AUTOSAR XML (schema 4-3-1)
standard types defined: Boolean, UInt8, SInt8, UInt16, SInt16, UInt32, SInt32, boolean, uint8, sint8, uint16, sint16, uint32, sint32
package /Components
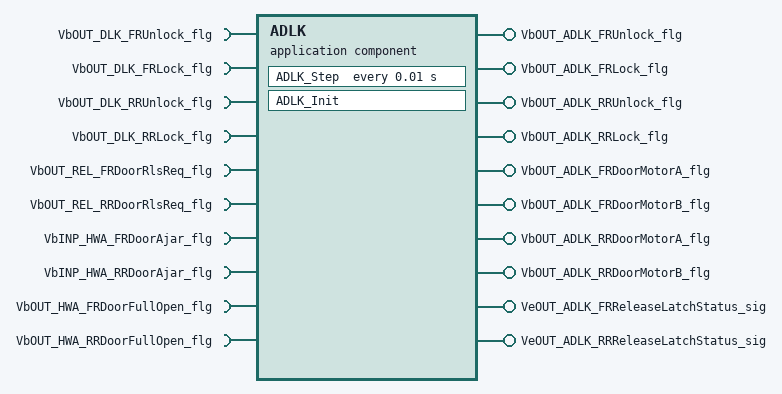
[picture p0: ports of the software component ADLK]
  application sw component type ADLK
    10 x require port:
      VbOUT_DLK_FRUnlock_flg: nonqueued-receiver-com-spec{data-element=VbOUT_DLK_FRUnlock_flg, init-value=FALSE}, required-interface=VbOUT_DLK_FRUnlock_flg
      VbOUT_DLK_FRLock_flg: nonqueued-receiver-com-spec{data-element=VbOUT_DLK_FRLock_flg, init-value=FALSE}, required-interface=VbOUT_DLK_FRLock_flg
      VbOUT_DLK_RRUnlock_flg: nonqueued-receiver-com-spec{data-element=VbOUT_DLK_RRUnlock_flg, init-value=FALSE}, required-interface=VbOUT_DLK_RRUnlock_flg
      VbOUT_DLK_RRLock_flg: nonqueued-receiver-com-spec{data-element=VbOUT_DLK_RRLock_flg, init-value=FALSE}, required-interface=VbOUT_DLK_RRLock_flg
      VbOUT_REL_FRDoorRlsReq_flg: nonqueued-receiver-com-spec{data-element=VbOUT_REL_FRDoorRlsReq_flg, init-value=FALSE}, required-interface=VbOUT_REL_FRDoorRlsReq_flg
      VbOUT_REL_RRDoorRlsReq_flg: nonqueued-receiver-com-spec{data-element=VbOUT_REL_RRDoorRlsReq_flg, init-value=FALSE}, required-interface=VbOUT_REL_RRDoorRlsReq_flg
      VbINP_HWA_FRDoorAjar_flg: nonqueued-receiver-com-spec{data-element=VbINP_HWA_FRDoorAjar_flg, init-value=FALSE}, required-interface=VbINP_HWA_FRDoorAjar_flg
      VbINP_HWA_RRDoorAjar_flg: nonqueued-receiver-com-spec{data-element=VbINP_HWA_RRDoorAjar_flg, init-value=FALSE}, required-interface=VbINP_HWA_RRDoorAjar_flg
      VbOUT_HWA_FRDoorFullOpen_flg: nonqueued-receiver-com-spec{data-element=VbOUT_HWA_FRDoorFullOpen_flg, init-value=FALSE}, required-interface=VbOUT_HWA_FRDoorFullOpen_flg
      VbOUT_HWA_RRDoorFullOpen_flg: nonqueued-receiver-com-spec{data-element=VbOUT_HWA_RRDoorFullOpen_flg, init-value=FALSE}, required-interface=VbOUT_HWA_RRDoorFullOpen_flg
    10 x provide port:
      VbOUT_ADLK_FRUnlock_flg: nonqueued-sender-com-spec{data-element=VbOUT_ADLK_FRUnlock_flg, init-value=FALSE}, provided-interface=VbOUT_ADLK_FRUnlock_flg
      VbOUT_ADLK_FRLock_flg: nonqueued-sender-com-spec{data-element=VbOUT_ADLK_FRLock_flg, init-value=FALSE}, provided-interface=VbOUT_ADLK_FRLock_flg
      VbOUT_ADLK_RRUnlock_flg: nonqueued-sender-com-spec{data-element=VbOUT_ADLK_RRUnlock_flg, init-value=FALSE}, provided-interface=VbOUT_ADLK_RRUnlock_flg
      VbOUT_ADLK_RRLock_flg: nonqueued-sender-com-spec{data-element=VbOUT_ADLK_RRLock_flg, init-value=FALSE}, provided-interface=VbOUT_ADLK_RRLock_flg
      VbOUT_ADLK_FRDoorMotorA_flg: nonqueued-sender-com-spec{data-element=VbOUT_ADLK_FRDoorMotorA_flg, init-value=FALSE}, provided-interface=VbOUT_ADLK_FRDoorMotorA_flg
      VbOUT_ADLK_FRDoorMotorB_flg: nonqueued-sender-com-spec{data-element=VbOUT_ADLK_FRDoorMotorB_flg, init-value=FALSE}, provided-interface=VbOUT_ADLK_FRDoorMotorB_flg
      VbOUT_ADLK_RRDoorMotorA_flg: nonqueued-sender-com-spec{data-element=VbOUT_ADLK_RRDoorMotorA_flg, init-value=FALSE}, provided-interface=VbOUT_ADLK_RRDoorMotorA_flg
      VbOUT_ADLK_RRDoorMotorB_flg: nonqueued-sender-com-spec{data-element=VbOUT_ADLK_RRDoorMotorB_flg, init-value=FALSE}, provided-interface=VbOUT_ADLK_RRDoorMotorB_flg
      VeOUT_ADLK_FRReleaseLatchStatus_sig: nonqueued-sender-com-spec{data-element=VeOUT_ADLK_FRReleaseLatchStatus_sig, init-value=0}, provided-interface=VeOUT_ADLK_FRReleaseLatchStatus_sig
      VeOUT_ADLK_RRReleaseLatchStatus_sig: nonqueued-sender-com-spec{data-element=VeOUT_ADLK_RRReleaseLatchStatus_sig, init-value=0}, provided-interface=VeOUT_ADLK_RRReleaseLatchStatus_sig
    behavior ADLK: data-type-mapping=DataTypeMappingsSet, handle-termination-and-restart=NO-SUPPORT
      init event ADLK_InitEvent: start-on-event=ADLK_Init
      timing event Event_Runnable_Step: start-on-event=ADLK_Step, period=0.01
      runnable ADLK_Init
        data-send-points:
          6 x access:
            OUT_VbOUT_ADLK_FRUnlock_flg_VbOUT_ADLK_FRUnlock_flg: accessed-variable=VbOUT_ADLK_FRUnlock_flg.VbOUT_ADLK_FRUnlock_flg
            OUT_VbOUT_ADLK_FRLock_flg_VbOUT_ADLK_FRLock_flg: accessed-variable=VbOUT_ADLK_FRLock_flg.VbOUT_ADLK_FRLock_flg
            OUT_VbOUT_ADLK_RRUnlock_flg_VbOUT_ADLK_RRUnlock_flg: accessed-variable=VbOUT_ADLK_RRUnlock_flg.VbOUT_ADLK_RRUnlock_flg
            OUT_VbOUT_ADLK_RRLock_flg_VbOUT_ADLK_RRLock_flg: accessed-variable=VbOUT_ADLK_RRLock_flg.VbOUT_ADLK_RRLock_flg
            OUT_VeOUT_ADLK_FRReleaseLatchStatus_sig_VeOUT_ADLK_FRReleaseLatchStatus_sig: accessed-variable=VeOUT_ADLK_FRReleaseLatchStatus_sig.VeOUT_ADLK_FRReleaseLatchStatus_sig
            OUT_VeOUT_ADLK_RRReleaseLatchStatus_sig_VeOUT_ADLK_RRReleaseLatchStatus_sig: accessed-variable=VeOUT_ADLK_RRReleaseLatchStatus_sig.VeOUT_ADLK_RRReleaseLatchStatus_sig
      runnable ADLK_Step
        data-receive-point-by-arguments:
          10 x access:
            IN_VbINP_HWA_FRDoorAjar_flg_VbINP_HWA_FRDoorAjar_flg: accessed-variable=VbINP_HWA_FRDoorAjar_flg.VbINP_HWA_FRDoorAjar_flg
            IN_VbINP_HWA_RRDoorAjar_flg_VbINP_HWA_RRDoorAjar_flg: accessed-variable=VbINP_HWA_RRDoorAjar_flg.VbINP_HWA_RRDoorAjar_flg
            IN_VbOUT_DLK_FRLock_flg_VbOUT_DLK_FRLock_flg: accessed-variable=VbOUT_DLK_FRLock_flg.VbOUT_DLK_FRLock_flg
            IN_VbOUT_DLK_FRUnlock_flg_VbOUT_DLK_FRUnlock_flg: accessed-variable=VbOUT_DLK_FRUnlock_flg.VbOUT_DLK_FRUnlock_flg
            IN_VbOUT_DLK_RRLock_flg_VbOUT_DLK_RRLock_flg: accessed-variable=VbOUT_DLK_RRLock_flg.VbOUT_DLK_RRLock_flg
            IN_VbOUT_DLK_RRUnlock_flg_VbOUT_DLK_RRUnlock_flg: accessed-variable=VbOUT_DLK_RRUnlock_flg.VbOUT_DLK_RRUnlock_flg
            IN_VbOUT_HWA_FRDoorFullOpen_flg_VbOUT_HWA_FRDoorFullOpen_flg: accessed-variable=VbOUT_HWA_FRDoorFullOpen_flg.VbOUT_HWA_FRDoorFullOpen_flg
            IN_VbOUT_HWA_RRDoorFullOpen_flg_VbOUT_HWA_RRDoorFullOpen_flg: accessed-variable=VbOUT_HWA_RRDoorFullOpen_flg.VbOUT_HWA_RRDoorFullOpen_flg
            IN_VbOUT_REL_FRDoorRlsReq_flg_VbOUT_REL_FRDoorRlsReq_flg: accessed-variable=VbOUT_REL_FRDoorRlsReq_flg.VbOUT_REL_FRDoorRlsReq_flg
            IN_VbOUT_REL_RRDoorRlsReq_flg_VbOUT_REL_RRDoorRlsReq_flg: accessed-variable=VbOUT_REL_RRDoorRlsReq_flg.VbOUT_REL_RRDoorRlsReq_flg
        data-send-points:
          10 x access:
            OUT_VbOUT_ADLK_FRUnlock_flg_VbOUT_ADLK_FRUnlock_flg: accessed-variable=VbOUT_ADLK_FRUnlock_flg.VbOUT_ADLK_FRUnlock_flg
            OUT_VbOUT_ADLK_FRLock_flg_VbOUT_ADLK_FRLock_flg: accessed-variable=VbOUT_ADLK_FRLock_flg.VbOUT_ADLK_FRLock_flg
            OUT_VbOUT_ADLK_RRUnlock_flg_VbOUT_ADLK_RRUnlock_flg: accessed-variable=VbOUT_ADLK_RRUnlock_flg.VbOUT_ADLK_RRUnlock_flg
            OUT_VbOUT_ADLK_RRLock_flg_VbOUT_ADLK_RRLock_flg: accessed-variable=VbOUT_ADLK_RRLock_flg.VbOUT_ADLK_RRLock_flg
            OUT_VbOUT_ADLK_FRDoorMotorA_flg_VbOUT_ADLK_FRDoorMotorA_flg: accessed-variable=VbOUT_ADLK_FRDoorMotorA_flg.VbOUT_ADLK_FRDoorMotorA_flg
            OUT_VbOUT_ADLK_FRDoorMotorB_flg_VbOUT_ADLK_FRDoorMotorB_flg: accessed-variable=VbOUT_ADLK_FRDoorMotorB_flg.VbOUT_ADLK_FRDoorMotorB_flg
            OUT_VbOUT_ADLK_RRDoorMotorA_flg_VbOUT_ADLK_RRDoorMotorA_flg: accessed-variable=VbOUT_ADLK_RRDoorMotorA_flg.VbOUT_ADLK_RRDoorMotorA_flg
            OUT_VbOUT_ADLK_RRDoorMotorB_flg_VbOUT_ADLK_RRDoorMotorB_flg: accessed-variable=VbOUT_ADLK_RRDoorMotorB_flg.VbOUT_ADLK_RRDoorMotorB_flg
            OUT_VeOUT_ADLK_FRReleaseLatchStatus_sig_VeOUT_ADLK_FRReleaseLatchStatus_sig: accessed-variable=VeOUT_ADLK_FRReleaseLatchStatus_sig.VeOUT_ADLK_FRReleaseLatchStatus_sig
            OUT_VeOUT_ADLK_RRReleaseLatchStatus_sig_VeOUT_ADLK_RRReleaseLatchStatus_sig: accessed-variable=VeOUT_ADLK_RRReleaseLatchStatus_sig.VeOUT_ADLK_RRReleaseLatchStatus_sig
package /DataTypes/ApplicationDataTypes
  application array data type rt_Array_UInt8_20: category=ARRAY, sw-calibration-access=READ-WRITE
    element rt_Array_UInt8_20: category=VALUE, type=UInt8, array-size-semantics=FIXED-SIZE, max-number-of-elements=20
  7 x app type, all with sw-calibration-access=READ-WRITE:
    Boolean: category=BOOLEAN, compu {0=FALSE, 1=TRUE}
    UInt8: category=VALUE, compu {identical}, range phys 0..255
    SInt8: category=VALUE, compu {identical}, range phys -128..127
    UInt16: category=VALUE, compu {identical}, range phys 0..65535
    SInt16: category=VALUE, compu {identical}, range phys -32768..32767
    UInt32: category=VALUE, compu {identical}, range phys 0..4294967295
    SInt32: category=VALUE, compu {identical}, range phys -2147483648..2147483647
package /DataTypes/DataTypeMappings
  data type mapping set DataTypeMappingsSet
    data-type-maps:
      application-data-type=Boolean, implementation-data-type=Boolean
      application-data-type=UInt8, implementation-data-type=UInt8
      application-data-type=SInt8, implementation-data-type=SInt8
      application-data-type=UInt16, implementation-data-type=UInt16
      application-data-type=SInt16, implementation-data-type=SInt16
      application-data-type=UInt32, implementation-data-type=UInt32
      application-data-type=SInt32, implementation-data-type=SInt32
      application-data-type=rt_Array_UInt8_20, implementation-data-type=rt_Array_UInt8_20
package /DataTypes/ImplementationDataTypes
  impl type rt_Array_UInt8_20: category=ARRAY
    element rt_Array_UInt8_20: array-size=20, array-size-semantics=FIXED-SIZE, implementation-data-type=UInt8
package /DataTypes/SwAddrMethods
  sw addr method CODE: section-type=CODE
  sw addr method CONST: section-type=CONST
  sw addr method VAR: section-type=VAR
package /DataTypes/Units
  unit NoUnit: factor-si-to-unit=1, offset-si-to-unit=0
package /Interfaces
  20 x sender receiver interface:
    VbOUT_DLK_FRUnlock_flg
      data VbOUT_DLK_FRUnlock_flg: category=BOOLEAN, sw-calibration-access=READ-ONLY, type=Boolean
    VbOUT_DLK_FRLock_flg
      data VbOUT_DLK_FRLock_flg: category=BOOLEAN, sw-calibration-access=READ-ONLY, type=Boolean
    VbOUT_DLK_RRUnlock_flg
      data VbOUT_DLK_RRUnlock_flg: category=BOOLEAN, sw-calibration-access=READ-ONLY, type=Boolean
    VbOUT_DLK_RRLock_flg
      data VbOUT_DLK_RRLock_flg: category=BOOLEAN, sw-calibration-access=READ-ONLY, type=Boolean
    VbOUT_REL_FRDoorRlsReq_flg
      data VbOUT_REL_FRDoorRlsReq_flg: category=BOOLEAN, sw-calibration-access=READ-ONLY, type=Boolean
    VbOUT_REL_RRDoorRlsReq_flg
      data VbOUT_REL_RRDoorRlsReq_flg: category=BOOLEAN, sw-calibration-access=READ-ONLY, type=Boolean
    VbINP_HWA_FRDoorAjar_flg
      data VbINP_HWA_FRDoorAjar_flg: category=BOOLEAN, sw-calibration-access=READ-ONLY, type=Boolean
    VbINP_HWA_RRDoorAjar_flg
      data VbINP_HWA_RRDoorAjar_flg: category=BOOLEAN, sw-calibration-access=READ-ONLY, type=Boolean
    VbOUT_HWA_FRDoorFullOpen_flg
      data VbOUT_HWA_FRDoorFullOpen_flg: category=BOOLEAN, sw-calibration-access=READ-ONLY, type=Boolean
    VbOUT_HWA_RRDoorFullOpen_flg
      data VbOUT_HWA_RRDoorFullOpen_flg: category=BOOLEAN, sw-calibration-access=READ-ONLY, type=Boolean
    VbOUT_ADLK_FRUnlock_flg
      data VbOUT_ADLK_FRUnlock_flg: category=BOOLEAN, sw-calibration-access=READ-ONLY, type=Boolean
    VbOUT_ADLK_FRLock_flg
      data VbOUT_ADLK_FRLock_flg: category=BOOLEAN, sw-calibration-access=READ-ONLY, type=Boolean
    VbOUT_ADLK_RRUnlock_flg
      data VbOUT_ADLK_RRUnlock_flg: category=BOOLEAN, sw-calibration-access=READ-ONLY, type=Boolean
    VbOUT_ADLK_RRLock_flg
      data VbOUT_ADLK_RRLock_flg: category=BOOLEAN, sw-calibration-access=READ-ONLY, type=Boolean
    VbOUT_ADLK_FRDoorMotorA_flg
      data VbOUT_ADLK_FRDoorMotorA_flg: category=BOOLEAN, sw-calibration-access=READ-ONLY, type=Boolean
    VbOUT_ADLK_FRDoorMotorB_flg
      data VbOUT_ADLK_FRDoorMotorB_flg: category=BOOLEAN, sw-calibration-access=READ-ONLY, type=Boolean
    VbOUT_ADLK_RRDoorMotorA_flg
      data VbOUT_ADLK_RRDoorMotorA_flg: category=BOOLEAN, sw-calibration-access=READ-ONLY, type=Boolean
    VbOUT_ADLK_RRDoorMotorB_flg
      data VbOUT_ADLK_RRDoorMotorB_flg: category=BOOLEAN, sw-calibration-access=READ-ONLY, type=Boolean
    VeOUT_ADLK_FRReleaseLatchStatus_sig
      data VeOUT_ADLK_FRReleaseLatchStatus_sig: category=VALUE, sw-calibration-access=READ-ONLY, type=UInt8
    VeOUT_ADLK_RRReleaseLatchStatus_sig
      data VeOUT_ADLK_RRReleaseLatchStatus_sig: category=VALUE, sw-calibration-access=READ-ONLY, type=UInt8
